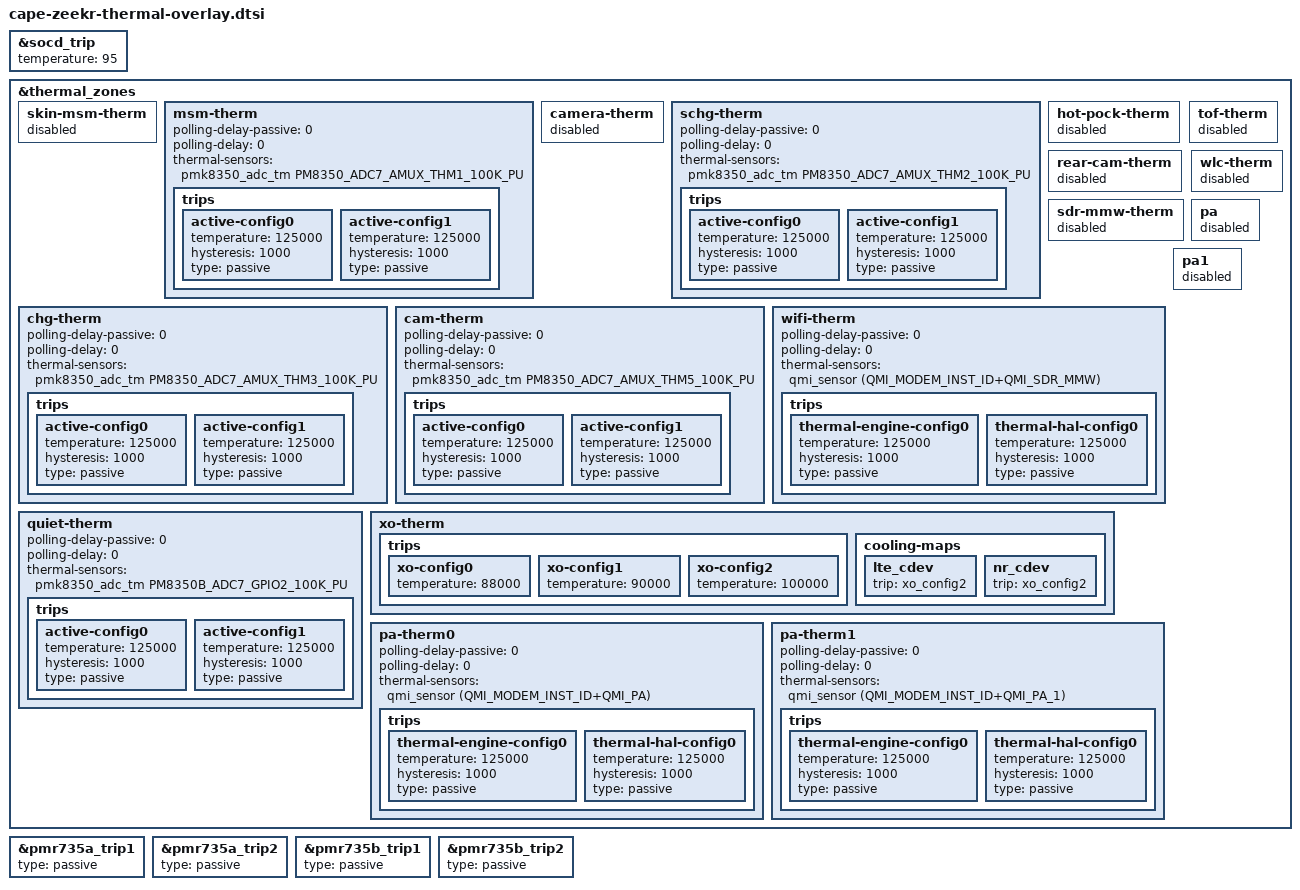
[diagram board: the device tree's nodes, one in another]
#include "moto_therm_sys_temp.dtsi"

&socd_trip {
    temperature = <95>;
};

&thermal_zones {
	skin-msm-therm {
		status = "disabled";
	};
	msm-therm {
		polling-delay-passive = <0>;
		polling-delay = <0>;
		thermal-sensors = <&pmk8350_adc_tm PM8350_ADC7_AMUX_THM1_100K_PU>;
		trips {
			active-config0 {
				temperature = <125000>;
				hysteresis = <1000>;
				type = "passive";
			};

			active-config1 {
				temperature = <125000>;
				hysteresis = <1000>;
				type = "passive";
			};
		};
	};

	camera-therm {
		status = "disabled";
	};
	schg-therm {
		polling-delay-passive = <0>;
		polling-delay = <0>;
		thermal-sensors = <&pmk8350_adc_tm PM8350_ADC7_AMUX_THM2_100K_PU>;
		trips {
			active-config0 {
				temperature = <125000>;
				hysteresis = <1000>;
				type = "passive";
			};

			active-config1 {
				temperature = <125000>;
				hysteresis = <1000>;
				type = "passive";
			};
		};
	};

	hot-pock-therm {
		status = "disabled";
	};
	chg-therm {
		polling-delay-passive = <0>;
		polling-delay = <0>;
		thermal-sensors = <&pmk8350_adc_tm PM8350_ADC7_AMUX_THM3_100K_PU>;
		trips {
			active-config0 {
				temperature = <125000>;
				hysteresis = <1000>;
				type = "passive";
			};

			active-config1 {
				temperature = <125000>;
				hysteresis = <1000>;
				type = "passive";
			};
		};
	};

	rear-cam-therm {
		status = "disabled";
	};
	tof-therm {
		status = "disabled";
	};
	cam-therm {
		polling-delay-passive = <0>;
		polling-delay = <0>;
		thermal-sensors = <&pmk8350_adc_tm PM8350_ADC7_AMUX_THM5_100K_PU>;
		trips {
			active-config0 {
				temperature = <125000>;
				hysteresis = <1000>;
				type = "passive";
			};

			active-config1 {
				temperature = <125000>;
				hysteresis = <1000>;
				type = "passive";
			};
		};
	};

	sdr-mmw-therm {
		status = "disabled";
	};
	wifi-therm {
		polling-delay-passive = <0>;
		polling-delay = <0>;
		thermal-sensors = <&qmi_sensor
				(QMI_MODEM_INST_ID+QMI_SDR_MMW)>;
		trips {
			thermal-engine-config0 {
				temperature = <125000>;
				hysteresis = <1000>;
				type = "passive";
			};

			thermal-hal-config0 {
				temperature = <125000>;
				hysteresis = <1000>;
				type = "passive";
			};
		};
	};

	wlc-therm {
		status = "disabled";
	};
	quiet-therm {
		polling-delay-passive = <0>;
		polling-delay = <0>;
		thermal-sensors = <&pmk8350_adc_tm PM8350B_ADC7_GPIO2_100K_PU>;
		trips {
			active-config0 {
				temperature = <125000>;
				hysteresis = <1000>;
				type = "passive";
			};

			active-config1 {
				temperature = <125000>;
				hysteresis = <1000>;
				type = "passive";
			};
		};
	};

	xo-therm {
		trips {
			xo-config0 {
				temperature = <88000>;
			};

			xo-config1 {
				temperature = <90000>;
			};

			xo-config2 {
				temperature = <100000>;
			};
		};
		cooling-maps {
			lte_cdev {
				trip = <&xo_config2>;
			};
			nr_cdev {
				trip = <&xo_config2>;
			};
		};
	};

	pa {
		status = "disabled";
	};
	pa-therm0 {
		polling-delay-passive = <0>;
		polling-delay = <0>;
		thermal-sensors = <&qmi_sensor
				(QMI_MODEM_INST_ID+QMI_PA)>;
		trips {
			thermal-engine-config0 {
				temperature = <125000>;
				hysteresis = <1000>;
				type = "passive";
			};

			thermal-hal-config0 {
				temperature = <125000>;
				hysteresis = <1000>;
				type = "passive";
			};
		};
	};

	pa1 {
		status = "disabled";
	};
	pa-therm1 {
		polling-delay-passive = <0>;
		polling-delay = <0>;
		thermal-sensors = <&qmi_sensor
				(QMI_MODEM_INST_ID+QMI_PA_1)>;
		trips {
			thermal-engine-config0 {
				temperature = <125000>;
				hysteresis = <1000>;
				type = "passive";
			};

			thermal-hal-config0 {
				temperature = <125000>;
				hysteresis = <1000>;
				type = "passive";
			};
		};
	};
};

&pmr735a_trip1 {
	type = "passive";
};

&pmr735a_trip2 {
	type = "passive";
};

&pmr735b_trip1 {
	type = "passive";
};

&pmr735b_trip2 {
	type = "passive";
};
